# STM32MP157 register map
File version: 1.6
CPU: CM4 r0p1, little endian, no MPU, FPU, 4 interrupt priority bits
Registers are 32-bit, read-write, reset 0x0 unless marked. A register's access mark holds for its fields unless they carry their own. Offsets are from the block's base; [hi:lo] are bit positions; {n}, {i} and the like mark numbered series; 'fields as' and 'values as' point back to an identical list.

## QUADSPI — QUADSPI1
Base 0x58003000
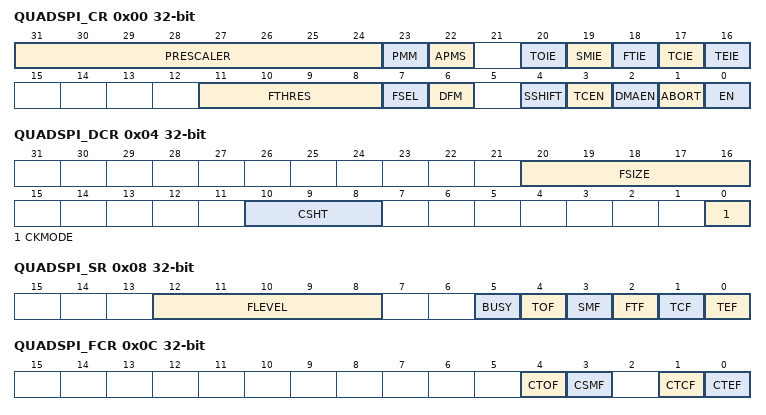
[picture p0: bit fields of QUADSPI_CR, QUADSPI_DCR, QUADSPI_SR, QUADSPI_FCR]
0x00 QUADSPI_CR — QUADSPI control register
  [31:24] PRESCALER, [23] PMM, [22] APMS, [20] TOIE, [19] SMIE, [18] FTIE, [17] TCIE, [16] TEIE, [11:8] FTHRES, [7] FSEL, [6] DFM, [4] SSHIFT, [3] TCEN, [2] DMAEN, [1] ABORT, [0] EN
0x04 QUADSPI_DCR — QUADSPI device configuration register
  [20:16] FSIZE, [10:8] CSHT, [0] CKMODE
0x08 QUADSPI_SR ro — QUADSPI status register
  [12:8] FLEVEL, [5] BUSY, [4] TOF, [3] SMF, [2] FTF, [1] TCF, [0] TEF
0x0C QUADSPI_FCR wo — QUADSPI flag clear register
  [4] CTOF, [3] CSMF, [1] CTCF, [0] CTEF
0x10 QUADSPI_DLR — QUADSPI data length register
  [31:0] DL
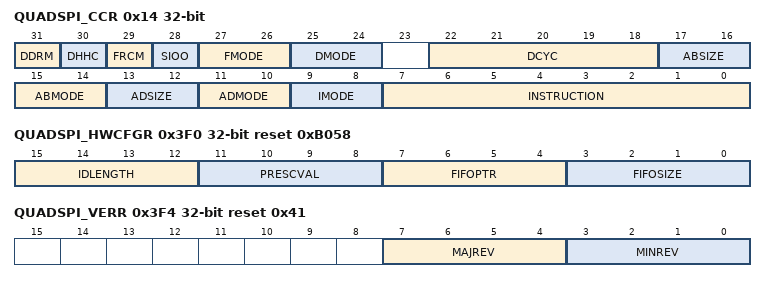
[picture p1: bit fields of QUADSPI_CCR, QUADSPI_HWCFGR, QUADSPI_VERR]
0x14 QUADSPI_CCR — QUADSPI communication configuration register
  [31] DDRM, [30] DHHC, [29] FRCM, [28] SIOO, [27:26] FMODE, [25:24] DMODE, [22:18] DCYC, [17:16] ABSIZE, [15:14] ABMODE, [13:12] ADSIZE, [11:10] ADMODE, [9:8] IMODE, [7:0] INSTRUCTION
0x18 QUADSPI_AR — QUADSPI address register
  [31:0] ADDRESS
0x1C QUADSPI_ABR — QUADSPI alternate bytes registers
  [31:0] ALTERNATE
0x20 QUADSPI_DR — QUADSPI data register
  [31:0] DATA
0x24 QUADSPI_PSMKR — QUADSPI polling status mask register
  [31:0] MASK
0x28 QUADSPI_PSMAR — QUADSPI polling status match register
  [31:0] MATCH
0x2C QUADSPI_PIR — QUADSPI polling interval register
  [15:0] INTERVAL
0x30 QUADSPI_LPTR — QUADSPI low-power timeout register
  [15:0] TIMEOUT
0x3F0 QUADSPI_HWCFGR ro reset 0xB058 — QUADSPI HW configuration register
  [15:12] IDLENGTH, [11:8] PRESCVAL, [7:4] FIFOPTR, [3:0] FIFOSIZE
0x3F4 QUADSPI_VERR ro reset 0x41 — QUADSPI version register
  [7:4] MAJREV, [3:0] MINREV
0x3F8 QUADSPI_IPIDR ro reset 0x140031 — QUADSPI identification register
  [31:0] ID
0x3FC QUADSPI_SIDR ro reset 0xA3C5DD01 — QUADSPI size identification register
  [31:0] SID

## RNG1
Base 0x54003000
Same registers: RNG2 0x4C003000
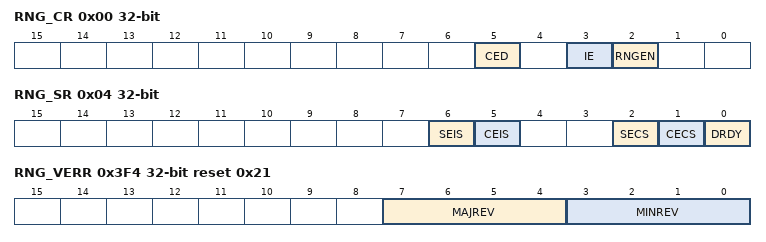
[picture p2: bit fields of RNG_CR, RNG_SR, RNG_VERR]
0x00 RNG_CR — RNG control register
  [5] CED, [3] IE, [2] RNGEN
0x04 RNG_SR access per field — RNG status register
  [6] SEIS rw, [5] CEIS rw, [2] SECS ro, [1] CECS ro, [0] DRDY ro
0x08 RNG_DR ro — The RNG_DR register is a read-only register.
  [31:0] RNDATA
0x3F0 RNG_HWCFGR ro reset 0x6 — RNG hardware configuration register
0x3F4 RNG_VERR ro reset 0x21 — RNG version register
  [7:4] MAJREV, [3:0] MINREV
0x3F8 RNG_IPIDR ro reset 0x170041 — RNG identification register
  [31:0] ID
0x3FC RNG_SIDR ro reset 0xA3C5DD01 — RNG size ID register
  [31:0] SID

## SAI1 — SAI1 register block
Base 0x4400A000
Same registers: SAI2 0x4400B000, SAI3 0x4400C000, SAI4 0x50027000
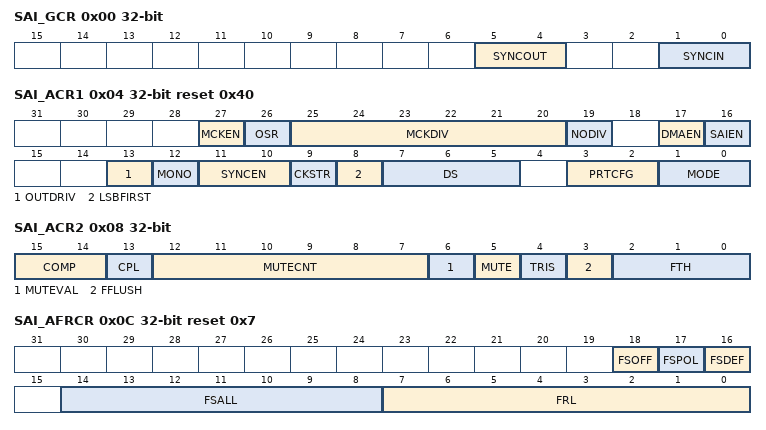
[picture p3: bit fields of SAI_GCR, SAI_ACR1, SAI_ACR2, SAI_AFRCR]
0x00 SAI_GCR — Global configuration register
  [5:4] SYNCOUT, [1:0] SYNCIN
0x04 SAI_ACR1 reset 0x40 — Configuration register 1
  [27] MCKEN, [26] OSR, [25:20] MCKDIV, [19] NODIV, [17] DMAEN, [16] SAIEN, [13] OUTDRIV, [12] MONO, [11:10] SYNCEN, [9] CKSTR, [8] LSBFIRST, [7:5] DS, [3:2] PRTCFG, [1:0] MODE
0x08 SAI_ACR2 access per field — Configuration register 2
  [15:14] COMP rw, [13] CPL rw, [12:7] MUTECNT rw, [6] MUTEVAL rw, [5] MUTE rw, [4] TRIS rw, [3] FFLUSH wo, [2:0] FTH rw
0x0C SAI_AFRCR access per field reset 0x7 — This register has no meaning in and SPDIF audio protocol
  [18] FSOFF rw, [17] FSPOL rw, [16] FSDEF ro, [14:8] FSALL rw, [7:0] FRL rw
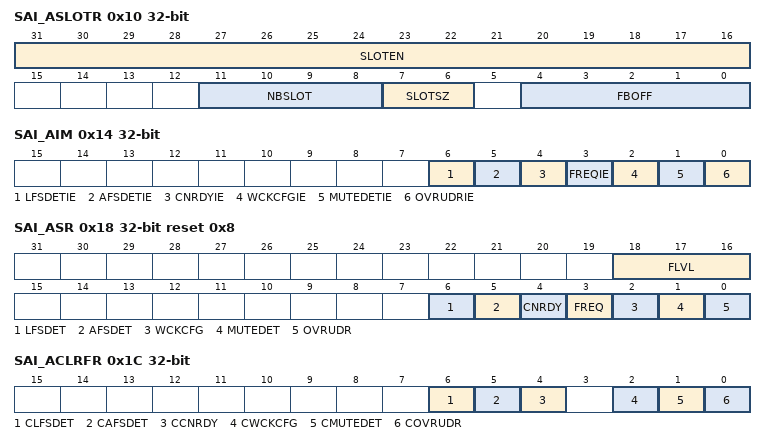
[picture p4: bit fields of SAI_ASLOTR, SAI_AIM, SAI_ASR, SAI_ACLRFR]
0x10 SAI_ASLOTR — This register has no meaning in and SPDIF audio protocol
  [31:16] SLOTEN, [11:8] NBSLOT, [7:6] SLOTSZ, [4:0] FBOFF
0x14 SAI_AIM — Interrupt mask register
  [6] LFSDETIE, [5] AFSDETIE, [4] CNRDYIE, [3] FREQIE, [2] WCKCFGIE, [1] MUTEDETIE, [0] OVRUDRIE
0x18 SAI_ASR ro reset 0x8 — Status register
  [18:16] FLVL, [6] LFSDET, [5] AFSDET, [4] CNRDY, [3] FREQ, [2] WCKCFG, [1] MUTEDET, [0] OVRUDR
0x1C SAI_ACLRFR wo — Clear flag register
  [6] CLFSDET, [5] CAFSDET, [4] CCNRDY, [2] CWCKCFG, [1] CMUTEDET, [0] COVRUDR
0x20 SAI_ADR — Data register
  [31:0] DATA
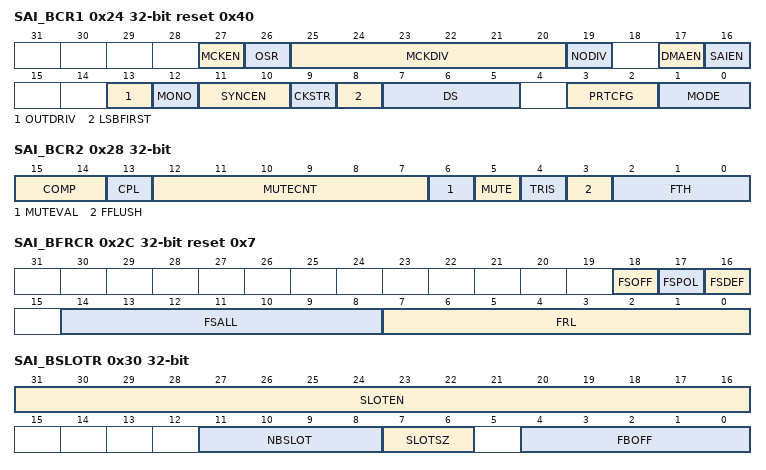
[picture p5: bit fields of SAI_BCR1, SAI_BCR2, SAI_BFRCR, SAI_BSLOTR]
0x24 SAI_BCR1 reset 0x40 — Configuration register 1
  fields as SAI_ACR1
0x28 SAI_BCR2 access per field — Configuration register 2
  fields as SAI_ACR2
0x2C SAI_BFRCR access per field reset 0x7 — This register has no meaning in and SPDIF audio protocol
  fields as SAI_AFRCR
0x30 SAI_BSLOTR — This register has no meaning in and SPDIF audio protocol
  [31:16] SLOTEN, [11:8] NBSLOT, [7:6] SLOTSZ, [4:0] FBOFF
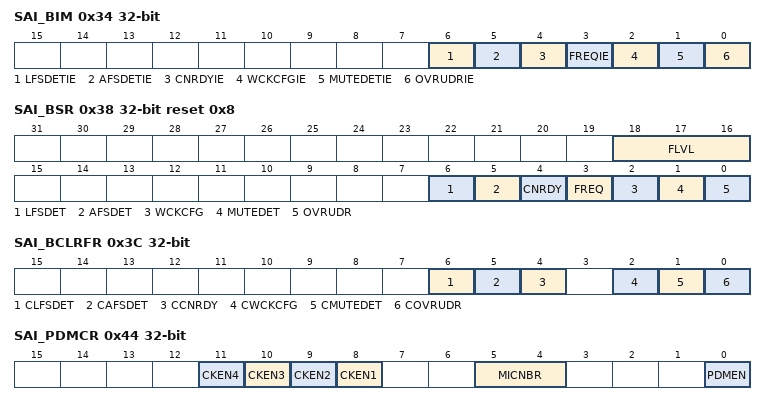
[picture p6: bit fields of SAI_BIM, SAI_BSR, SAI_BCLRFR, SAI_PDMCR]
0x34 SAI_BIM — Interrupt mask register
  fields as SAI_AIM
0x38 SAI_BSR ro reset 0x8 — Status register
  fields as SAI_ASR
0x3C SAI_BCLRFR wo — Clear flag register
  fields as SAI_ACLRFR
0x40 SAI_BDR — Data register
  [31:0] DATA
0x44 SAI_PDMCR — PDM control register
  [n+7] CKEN{n} (n=1..4), [5:4] MICNBR, [0] PDMEN
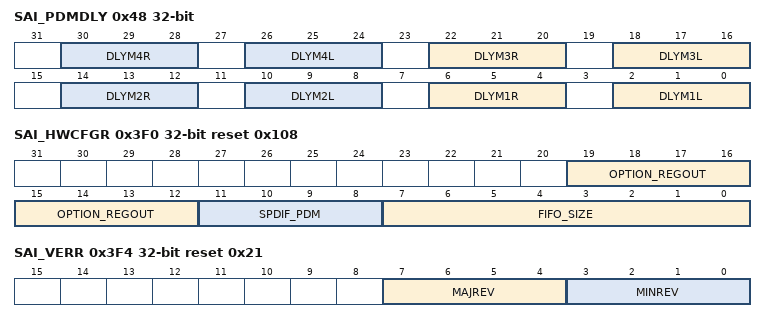
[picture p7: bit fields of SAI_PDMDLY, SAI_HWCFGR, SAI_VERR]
0x48 SAI_PDMDLY — PDM delay register
  [8n-2:8n-4] DLYM{n}R (n=1..4), [8n-6:8n-8] DLYM{n}L (n=1..4)
0x3F0 SAI_HWCFGR ro reset 0x108 — SAI hardware configuration register
  [19:12] OPTION_REGOUT, [11:8] SPDIF_PDM, [7:0] FIFO_SIZE
0x3F4 SAI_VERR ro reset 0x21 — SAI version register
  [7:4] MAJREV, [3:0] MINREV
0x3F8 SAI_IPIDR ro reset 0x130031 — SAI identification register
  [31:0] ID
0x3FC SAI_SIDR ro reset 0xA3C5DD01 — SAI size identification register
  [31:0] SID
